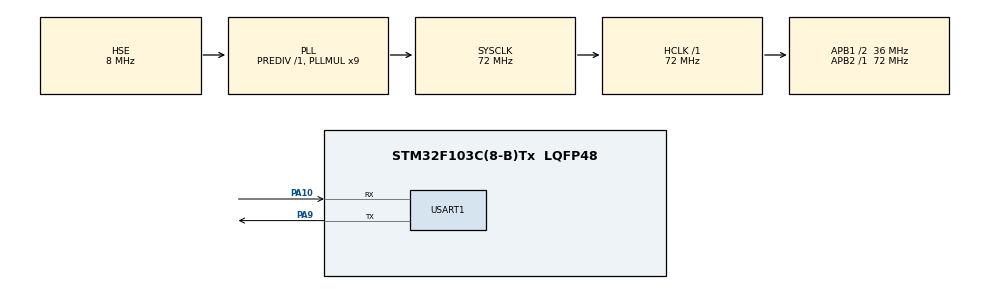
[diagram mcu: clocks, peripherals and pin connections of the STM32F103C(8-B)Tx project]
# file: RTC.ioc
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Mcu.Family=STM32F1
Mcu.Name=STM32F103C(8-B)Tx
Mcu.Package=LQFP48
NVIC.PriorityGroup=NVIC_PRIORITYGROUP_4
NVIC.RTC_Alarm_IRQn=true\:0\:0\:false\:false\:true\:true\:true
PA10.Mode=Asynchronous
PA10.Signal=USART1_RX
PA13.Mode=Serial_Wire
PA13.Signal=SYS_JTMS-SWDIO
PA14.Mode=Serial_Wire
PA14.Signal=SYS_JTCK-SWCLK
PA9.Mode=Asynchronous
PA9.Signal=USART1_TX
PC14-OSC32_IN.Mode=LSE-External-Oscillator
PC14-OSC32_IN.Signal=RCC_OSC32_IN
PC15-OSC32_OUT.Mode=LSE-External-Oscillator
PC15-OSC32_OUT.Signal=RCC_OSC32_OUT
PD0-OSC_IN.Mode=HSE-External-Oscillator
PD0-OSC_IN.Signal=RCC_OSC_IN
PD1-OSC_OUT.Mode=HSE-External-Oscillator
PD1-OSC_OUT.Signal=RCC_OSC_OUT
ProjectManager.HeapSize=0x200
ProjectManager.StackSize=0x400
ProjectManager.TargetToolchain=STM32CubeIDE
RCC.AHBFreq_Value=72000000
RCC.APB1CLKDivider=RCC_HCLK_DIV2
RCC.APB1Freq_Value=36000000
RCC.APB1TimFreq_Value=72000000
RCC.APB2Freq_Value=72000000
RCC.APB2TimFreq_Value=72000000
RCC.HCLKFreq_Value=72000000
RCC.PLLMUL=RCC_PLL_MUL9
RCC.PLLSourceVirtual=RCC_PLLSOURCE_HSE
RCC.RTCClockSelection=RCC_RTCCLKSOURCE_LSE
RCC.SYSCLKFreq_VALUE=72000000
RCC.SYSCLKSource=RCC_SYSCLKSOURCE_PLLCLK
RCC.USBFreq_Value=72000000
RTC.AutoPrediv=RTC_AUTO_1_SECOND
RTC.Date=30
RTC.Hours=12
RTC.Minutes=0
RTC.Month=RTC_MONTH_APRIL
RTC.OutPut=RTC_OUTPUTSOURCE_NONE
RTC.WeekDay=RTC_WEEKDAY_THURSDAY
RTC.Year=20
USART1.VirtualMode=VM_ASYNC
VP_RTC_No_RTC_Output.Mode=RTC_OUT_NO
VP_RTC_VS_RTC_Activate.Mode=RTC_Enabled
VP_RTC_VS_RTC_Calendar.Mode=RTC_Calendar
board=custom

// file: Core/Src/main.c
/* USER CODE BEGIN Header */
/**
  ******************************************************************************
  * @file           : main.c
  * @brief          : Main program body
  ******************************************************************************
  * @attention
  *
  * <h2><center>&copy; Copyright (c) 2020 STMicroelectronics.
  * All rights reserved.</center></h2>
  *
  * This software component is licensed by ST under BSD 3-Clause license,
  * the "License"; You may not use this file except in compliance with the
  * License. You may obtain a copy of the License at:
  *                        opensource.org/licenses/BSD-3-Clause
  *
  ******************************************************************************
  */
/* USER CODE END Header */

#include "main.h"

/* USER CODE BEGIN Includes */
#include "stdio.h"
#include "stdlib.h"
/* USER CODE END Includes */

RTC_HandleTypeDef hrtc;

UART_HandleTypeDef huart1;

void SystemClock_Config(void);
static void MX_GPIO_Init(void);
static void MX_RTC_Init(void);
static void MX_USART1_UART_Init(void);
/* USER CODE BEGIN PFP */
static void Set_Time(void);
static void Set_Date(void);
static void Set_Alarm(void);

void HAL_RTC_AlarmAEventCallback(RTC_HandleTypeDef * hrtc);
/* USER CODE END PFP */

/* USER CODE BEGIN 0 */
/*
 * Sets the time.
 */
static void Set_Time(void)
{

	RTC_TimeTypeDef sTime = {0};

	sTime.Hours = 0x12;
	sTime.Minutes = 0x00;
	sTime.Seconds = 0x00;

	if (HAL_RTC_SetTime(&hrtc, &sTime, RTC_FORMAT_BCD) != HAL_OK)
	{
	  Error_Handler();
	}

	return;
}

/*
 * Sets the date.
 */
static void Set_Date(void)
{
	RTC_DateTypeDef DateToUpdate = {0};

	DateToUpdate.WeekDay = RTC_WEEKDAY_THURSDAY;
	DateToUpdate.Month = RTC_MONTH_APRIL;
	DateToUpdate.Date = 0x30;
	DateToUpdate.Year = 0x20;

	if (HAL_RTC_SetDate(&hrtc, &DateToUpdate, RTC_FORMAT_BCD) != HAL_OK)
	{
	  Error_Handler();
	}

	return;
}

/*
 * Sets the alarm in interrupt mode.
 */
static void Set_Alarm(void)
{
	RTC_AlarmTypeDef gAlarm = {0};

	gAlarm.Alarm = 1;

	gAlarm.AlarmTime.Hours = 0x12;
	gAlarm.AlarmTime.Minutes = 0x00;
	gAlarm.AlarmTime.Seconds = 0x15;

	if(HAL_RTC_SetAlarm_IT(&hrtc, &gAlarm, RTC_FORMAT_BCD) != HAL_OK)
	{
		Error_Handler();
	}

	return;
}

/*
 * Alarm event handler. Interrupt happens when actual time is equals to alarm
 */
void HAL_RTC_AlarmAEventCallback (RTC_HandleTypeDef * hrtc)
{
	uint8_t alarmArray[] = "Alarm!\n";
	HAL_UART_Transmit(&huart1, alarmArray, sizeof(alarmArray), 200);

	return;
}

/* USER CODE END 0 */

int main(void)
{

  /* MCU Configuration--------------------------------------------------------*/

  /* Reset of all peripherals, Initializes the Flash interface and the Systick. */
  HAL_Init();

  /* Configure the system clock */
  SystemClock_Config();

  /* Initialize all configured peripherals */
  MX_GPIO_Init();
  MX_RTC_Init();
  MX_USART1_UART_Init();
  /* USER CODE BEGIN 2 */

  //This sentence evaluates if time/date/alarm was already updated
  if(HAL_RTCEx_BKUPRead(&hrtc, RTC_BKP_DR1) != 0x32F2)
  {
  //Set the time, date and alarm
	  Set_Time();
  	  Set_Date();
  	  Set_Alarm();
  	  //This is used to store value even when uC is restarted (using backup battery/supply)
  	  HAL_RTCEx_BKUPWrite(&hrtc, RTC_BKP_DR1, 0x32F2);
  }

  /* USER CODE END 2 */

  /* Infinite loop */
  /* USER CODE BEGIN WHILE */
  RTC_TimeTypeDef gTime;	//Time struct variable
  uint8_t time[10];			//Array to store time as string. Format: hh:mm:ss
  while (1)
  {
	  //Function call to get time. Returns hours, minutes and seconds on gTime struct variable.
	  HAL_RTC_GetTime(&hrtc, &gTime, RTC_FORMAT_BIN);
	  //Function call to store as string second argument into first argument. Returns number of bytes of string copied.
	  uint8_t sizeBuffer = sprintf((char *)time, "%02u:%02u:%02u\n", gTime.Hours, gTime.Minutes, gTime.Seconds);

	  //Function call to transmit time array through serial port
	  HAL_UART_Transmit(&huart1, time, sizeBuffer, 500);
	  //Wait for 1 second (1000 ms)
	  HAL_Delay(1000);
    /* USER CODE END WHILE */

  }
}

void SystemClock_Config(void)
{
  RCC_OscInitTypeDef RCC_OscInitStruct = {0};
  RCC_ClkInitTypeDef RCC_ClkInitStruct = {0};
  RCC_PeriphCLKInitTypeDef PeriphClkInit = {0};

  /** Initializes the CPU, AHB and APB busses clocks
  */
  RCC_OscInitStruct.OscillatorType = RCC_OSCILLATORTYPE_HSE|RCC_OSCILLATORTYPE_LSE;
  RCC_OscInitStruct.HSEState = RCC_HSE_ON;
  RCC_OscInitStruct.HSEPredivValue = RCC_HSE_PREDIV_DIV1;
  RCC_OscInitStruct.LSEState = RCC_LSE_ON;
  RCC_OscInitStruct.HSIState = RCC_HSI_ON;
  RCC_OscInitStruct.PLL.PLLState = RCC_PLL_ON;
  RCC_OscInitStruct.PLL.PLLSource = RCC_PLLSOURCE_HSE;
  RCC_OscInitStruct.PLL.PLLMUL = RCC_PLL_MUL9;
  if (HAL_RCC_OscConfig(&RCC_OscInitStruct) != HAL_OK)
  {
    Error_Handler();
  }
  /** Initializes the CPU, AHB and APB busses clocks
  */
  RCC_ClkInitStruct.ClockType = RCC_CLOCKTYPE_HCLK|RCC_CLOCKTYPE_SYSCLK
                              |RCC_CLOCKTYPE_PCLK1|RCC_CLOCKTYPE_PCLK2;
  RCC_ClkInitStruct.SYSCLKSource = RCC_SYSCLKSOURCE_PLLCLK;
  RCC_ClkInitStruct.AHBCLKDivider = RCC_SYSCLK_DIV1;
  RCC_ClkInitStruct.APB1CLKDivider = RCC_HCLK_DIV2;
  RCC_ClkInitStruct.APB2CLKDivider = RCC_HCLK_DIV1;

  if (HAL_RCC_ClockConfig(&RCC_ClkInitStruct, FLASH_LATENCY_2) != HAL_OK)
  {
    Error_Handler();
  }
  PeriphClkInit.PeriphClockSelection = RCC_PERIPHCLK_RTC;
  PeriphClkInit.RTCClockSelection = RCC_RTCCLKSOURCE_LSE;
  if (HAL_RCCEx_PeriphCLKConfig(&PeriphClkInit) != HAL_OK)
  {
    Error_Handler();
  }
}

static void MX_RTC_Init(void)
{

//  RTC_TimeTypeDef sTime = {0};
//  RTC_DateTypeDef DateToUpdate = {0};

  /** Initialize RTC Only
  */
  hrtc.Instance = RTC;
  hrtc.Init.AsynchPrediv = RTC_AUTO_1_SECOND;
  hrtc.Init.OutPut = RTC_OUTPUTSOURCE_NONE;
  if (HAL_RTC_Init(&hrtc) != HAL_OK)
  {
    Error_Handler();
  }

  /** Initialize RTC and set the Time and Date
  */
//  sTime.Hours = 0x12;
//  sTime.Minutes = 0x0;
//  sTime.Seconds = 0x0;
//
//  if (HAL_RTC_SetTime(&hrtc, &sTime, RTC_FORMAT_BCD) != HAL_OK)
//  {
//    Error_Handler();
//  }
//  DateToUpdate.WeekDay = RTC_WEEKDAY_THURSDAY;
//  DateToUpdate.Month = RTC_MONTH_APRIL;
//  DateToUpdate.Date = 0x30;
//  DateToUpdate.Year = 0x20;
//
//  if (HAL_RTC_SetDate(&hrtc, &DateToUpdate, RTC_FORMAT_BCD) != HAL_OK)
//  {
//    Error_Handler();
//  }

}

static void MX_USART1_UART_Init(void)
{

  huart1.Instance = USART1;
  huart1.Init.BaudRate = 115200;
  huart1.Init.WordLength = UART_WORDLENGTH_8B;
  huart1.Init.StopBits = UART_STOPBITS_1;
  huart1.Init.Parity = UART_PARITY_NONE;
  huart1.Init.Mode = UART_MODE_TX_RX;
  huart1.Init.HwFlowCtl = UART_HWCONTROL_NONE;
  huart1.Init.OverSampling = UART_OVERSAMPLING_16;
  if (HAL_UART_Init(&huart1) != HAL_OK)
  {
    Error_Handler();
  }

}

static void MX_GPIO_Init(void)
{

  /* GPIO Ports Clock Enable */
  __HAL_RCC_GPIOC_CLK_ENABLE();
  __HAL_RCC_GPIOD_CLK_ENABLE();
  __HAL_RCC_GPIOA_CLK_ENABLE();

}

void Error_Handler(void)
{
}

/************************ (C) COPYRIGHT STMicroelectronics *****END OF FILE****/
